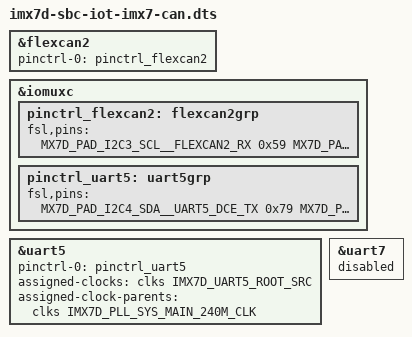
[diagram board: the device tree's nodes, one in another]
/*
 * Support for CompuLab SBC-IOT-iMX7 Single Board Computer with CAN bus support
 *
 * Copyright (C) 2017 CompuLab Ltd. - http://www.compulab.co.il/
 * Author: Ilya Ledvich <ilya@compulab.co.il>
 *
 * This file is dual-licensed: you can use it either under the terms
 * of the GPL or the X11 license, at your option. Note that this dual
 * licensing only applies to this file, and not this project as a
 * whole.
 */

#include "imx7d-sbc-iot-imx7.dts"

&flexcan2 {
	pinctrl-names = "default";
	pinctrl-0 = <&pinctrl_flexcan2>;
	status = "okay";
};

&iomuxc {
	pinctrl_flexcan2: flexcan2grp {
		fsl,pins = <
			MX7D_PAD_I2C3_SCL__FLEXCAN2_RX		0x59
			MX7D_PAD_I2C3_SDA__FLEXCAN2_TX		0x59
		>;
	};

	pinctrl_uart5: uart5grp {
		fsl,pins = <
			MX7D_PAD_I2C4_SDA__UART5_DCE_TX		0x79 /* RS232-TX */
			MX7D_PAD_I2C4_SCL__UART5_DCE_RX		0x79 /* RS232-RX */
		>;
	};
};

&uart5 {
	pinctrl-names = "default";
	pinctrl-0 = <&pinctrl_uart5>;
	assigned-clocks = <&clks IMX7D_UART5_ROOT_SRC>;
	assigned-clock-parents = <&clks IMX7D_PLL_SYS_MAIN_240M_CLK>;
	status = "okay";
};

&uart7 {
	status = "disabled";
};
